# MIMXRT685S_cm33 register map
Vendor: nxp.com; File version: 1.0
CPU: CM33 r2p0, little endian, MPU, FPU, VTOR, 3 interrupt priority bits
Registers are 32-bit, read-write, reset 0x0 unless marked. A register's access mark holds for its fields unless they carry their own. Offsets are from the block's base; [hi:lo] are bit positions; lines under a group give offsets from that group; {n}, {i} and the like mark numbered series; 'fields as' and 'values as' point back to an identical list.

## DMIC0 — LPC_Next0 DMIC Subsystem (DMIC))
Base 0x40121000
{0x0+0x100*i} CHANNEL[{i}] (i=0..7) group
  0x00 OSR — CIC Filter decimation rate
    [7:0] OSR — Selects the oversample rate for the related input channel.
  0x04 DIVHFCLK — Divider for generating PDM clock from DMIC clock input
    [3:0] PDMDIV — Divide by factor to create PDM Clock (enumerated type)
  0x08 PREAC2FSCOEF — Compensation filter for 2FS
    [1:0] COMP — Co-efficient choice for CIC droop compensation droop filter
  0x0C PREAC4FSCOEF — Compensation filter for 4FS
    fields as CHANNEL[0].PREAC2FSCOEF
  0x10 GAINSHIFT — Decimator output gain adjustment
    [5:0] GAIN — Gain shift for decimator output (can be positive or negative number)
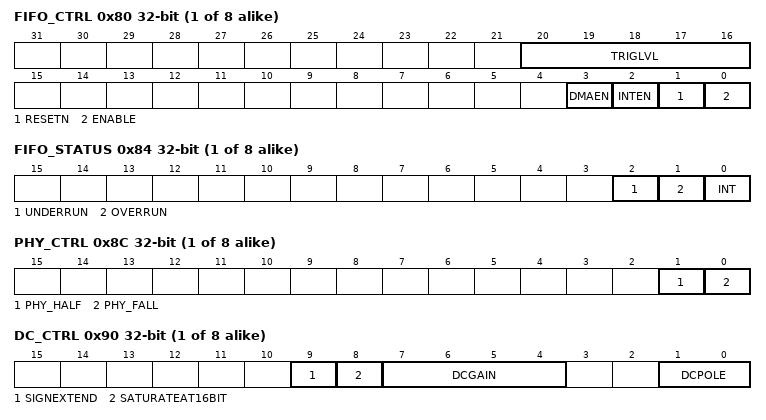
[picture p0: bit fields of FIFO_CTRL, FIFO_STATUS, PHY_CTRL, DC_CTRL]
  0x80 FIFO_CTRL — FIFO Control
    [20:16] TRIGLVL — Trigger level for interrupt
    [3] DMAEN — DMA enable
      0=DISABLED (DMA requests are not enabled.); 1=ENABLED (DMA requests based on FIFO level are enabled.)
    [2] INTEN — Interrupt enable.
      0=DISABLED (FIFO level interrupts are not enabled.); 1=ENABLED (FIFO level interrupts are enabled.)
    [1] RESETN — FIFO reset.
      0=RESET (Reset the FIFO.); 1=NORMAL (Normal operation)
    [0] ENABLE — FIFO enable.
      0=DISABLED (FIFO is not enabled. Enabling a DMIC channel with the FIFO disabled could be useful while data is being streamed to the I2S, or in order to avoid a filter settling delay when a channel is re-enabled after a period when the data was not needed.); 1=ENABLED (FIFO is enabled. The FIFO must be enabled in order for the CPU or DMA to read data from the DMIC via the FIFODATA register.)
  0x84 FIFO_STATUS
    [2] UNDERRUN — Underrun Detected (write 1 to clear)
    [1] OVERRUN — Overrun Detected (write 1 to clear)
    [0] INT — Status of Interrupt (write 1 to clear)
  0x88 FIFO_DATA ro
    [23:0] DATA — PCM Data
  0x8C PHY_CTRL
    [1] PHY_HALF — Use Half rate sampling (ie Clock to dmic is sent at half the speed than the decimator is providing)
      0=STANDARD (Standard half rate sampling. The clock to the DMIC is sent at the same rate as the decimator is providing.); 1=HALF_RATE (Use half rate sampling. The clock to the DMIC is sent at half the rate as the decimator is providing.)
    [0] PHY_FALL — Capture DMIC on Falling edge (0 means on rising)
      0=RISING_EDGE (Capture PDM_DATA on the rising edge of PDM_CLK.); 1=FALLING_EDGE (Capture PDM_DATA on the falling edge of PDM_CLK.)
  0x90 DC_CTRL — DC Filter Control
    [9] SIGNEXTEND
      0=DO_NOT_SIGNEXTEND (The top byte of the FIFODATA register is always 0.); 1=SIGNEXTEND (The top byte of the FIFODATA register is sign extended. This allows processing of 24-bit audio data on 32-bit machines.)
    [8] SATURATEAT16BIT — Selects 16-bit saturation.
      0=DO_NOT_SATURATE (Results roll over if out range and do not saturate.); 1=SATURATE (If the result overflows, it saturates at 0xFFFF for positive overflow and 0x8000 for negative overflow.)
    [7:4] DCGAIN — Fine gain adjustment in the form of a number of bits to downshift.
    [1:0] DCPOLE — DC block filter
      0=FLAT_RESPONSE (Flat response, no filter.); 1=HZ_155 (155 Hz.); 2=HZ_78 (78 Hz.); 3=HZ_39 (39 Hz)
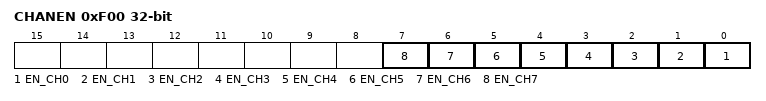
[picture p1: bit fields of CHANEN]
0xF00 CHANEN (reset mask 0x3) — Channel Enable register
  [n] EN_CH{n} (n=0..7) — Enable channel {n}. When 1, PDM channel {n} is enabled.
0xF10 USE2FS
  [0] USE2FS
    0=USE_1FS (Use 1FS output for PCM data.); 1=USE_2FS (Use 2FS output for PCM data.)
0xF14 GLOBAL_SYNC_EN — global sync enable
  [7:0] CH_SYNC_EN — Choose which channels to sync to global sync (7:0) corresponds to the 8 channels
0xF18 GLOBAL_COUNT_VAL
  [31:0] CCOUNTVAL — 32bit value, global sync counter will trigger a pulse whenever count reaches GCOUNTVAL
0xF1C DECRESET
  [7:0] DECRESET
    0=RELEASE_RESET (release reset to decimator); 1=ASSERT_RESET (assert reset to decimator Note : resets are applied in pairs. So bit 0 corresponds to channels 0/1, bit1 corresponds to channels 2/3, bit2 to channel 4/5 and bit3 to channel 6/7)
0xF80 HWVADGAIN reset 0x5 — HWVAD input gain register
  [3:0] INPUTGAIN — Gain factor for input signal into HWVAD
0xF84 HWVADHPFS reset 0x1 — HWVAD filter control register
  [1:0] HPFS — This field chooses the High Pass filter in first part of HWVAD
    0=BYPASS (First filter by-pass.); 1=HIGH_PASS_1750HZ (High pass filter with -3dB cut-off at 1750Hz.); 2=HIGH_PASS_215HZ (High pass filter with -3dB cut-off at 215Hz.)
0xF88 HWVADST10 — HWVAD control register
  [0] ST10 — 1' means enter stage 1 of VAD, ie a sound change has been detected and the HWVAD is being allowed to settle. Use 0 when changing back to detection mode. Allow several milliseconds in stage 1 for settling.
    0=NORMAL (Normal operation, waiting for HWVAD trigger event (stage 0).); 1=RESET (Reset internal interrupt flag by writing a '1' pulse.)
0xF8C HWVADRSTT — HWVAD filter reset register
  [0] RSTT — Reset HWVAD. Write back to 0 to release reset.
0xF90 HWVADTHGN — HWVAD noise estimator gain register
  [3:0] THGN — Gain Factor for Noise-floor - use a positive number to make average less sensitive to sudden changes
0xF94 HWVADTHGS reset 0x4 — HWVAD signal estimator gain register
  [3:0] THGS — Signal Gain factor - use a postive number to make current signal stand out more over longer term average
0xF98 HWVADLOWZ ro — HWVAD noise envelope estimator register
  [15:0] LOWZ — Average noise-floor value
